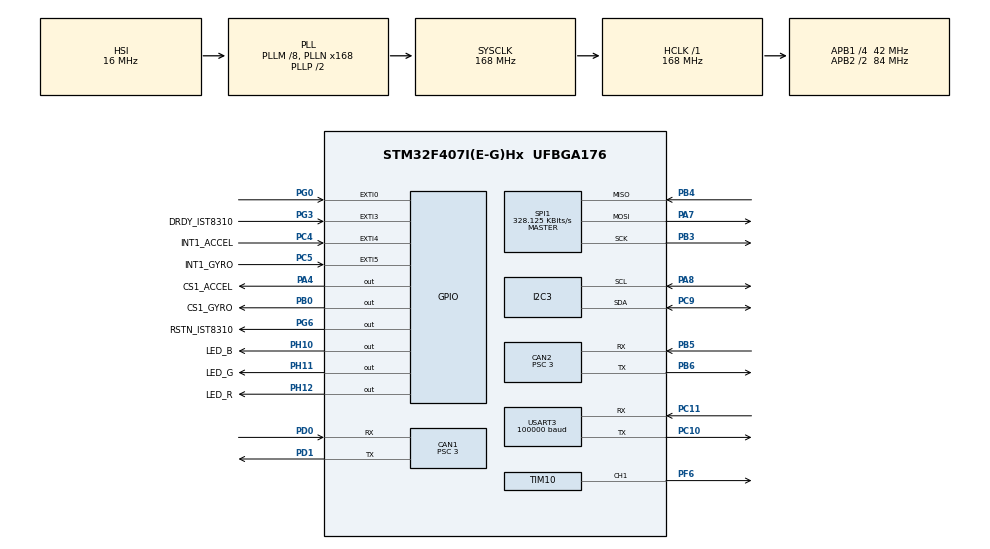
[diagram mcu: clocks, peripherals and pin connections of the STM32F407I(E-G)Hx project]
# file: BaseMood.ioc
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CAN1.BS1=CAN_BS1_11TQ
CAN1.BS2=CAN_BS2_2TQ
CAN1.CalculateBaudRate=1000000
CAN1.CalculateTimeBit=1000
CAN1.CalculateTimeQuantum=71.42857142857143
CAN1.Prescaler=3
CAN2.BS1=CAN_BS1_11TQ
CAN2.BS2=CAN_BS2_2TQ
CAN2.CalculateBaudRate=1000000
CAN2.CalculateTimeBit=1000
CAN2.CalculateTimeQuantum=71.42857142857143
CAN2.Prescaler=3
Dma.Request0=SPI1_RX
Dma.Request1=SPI1_TX
Dma.Request2=USART3_RX
Dma.SPI1_RX.0.Direction=DMA_PERIPH_TO_MEMORY
Dma.SPI1_RX.0.FIFOMode=DMA_FIFOMODE_DISABLE
Dma.SPI1_RX.0.Instance=DMA2_Stream2
Dma.SPI1_RX.0.MemDataAlignment=DMA_MDATAALIGN_BYTE
Dma.SPI1_RX.0.MemInc=DMA_MINC_ENABLE
Dma.SPI1_RX.0.Mode=DMA_NORMAL
Dma.SPI1_RX.0.PeriphDataAlignment=DMA_PDATAALIGN_BYTE
Dma.SPI1_RX.0.PeriphInc=DMA_PINC_DISABLE
Dma.SPI1_RX.0.Priority=DMA_PRIORITY_VERY_HIGH
Dma.SPI1_TX.1.Direction=DMA_MEMORY_TO_PERIPH
Dma.SPI1_TX.1.FIFOMode=DMA_FIFOMODE_DISABLE
Dma.SPI1_TX.1.Instance=DMA2_Stream3
Dma.SPI1_TX.1.MemDataAlignment=DMA_MDATAALIGN_BYTE
Dma.SPI1_TX.1.MemInc=DMA_MINC_ENABLE
Dma.SPI1_TX.1.Mode=DMA_NORMAL
Dma.SPI1_TX.1.PeriphDataAlignment=DMA_PDATAALIGN_BYTE
Dma.SPI1_TX.1.PeriphInc=DMA_PINC_DISABLE
Dma.SPI1_TX.1.Priority=DMA_PRIORITY_HIGH
Dma.USART3_RX.2.Direction=DMA_PERIPH_TO_MEMORY
Dma.USART3_RX.2.FIFOMode=DMA_FIFOMODE_DISABLE
Dma.USART3_RX.2.Instance=DMA1_Stream1
Dma.USART3_RX.2.MemDataAlignment=DMA_MDATAALIGN_BYTE
Dma.USART3_RX.2.MemInc=DMA_MINC_ENABLE
Dma.USART3_RX.2.Mode=DMA_CIRCULAR
Dma.USART3_RX.2.PeriphDataAlignment=DMA_PDATAALIGN_BYTE
Dma.USART3_RX.2.PeriphInc=DMA_PINC_DISABLE
Dma.USART3_RX.2.Priority=DMA_PRIORITY_MEDIUM
FREERTOS.INCLUDE_pcTaskGetTaskName=1
FREERTOS.INCLUDE_uxTaskGetStackHighWaterMark2=1
FREERTOS.INCLUDE_vTaskCleanUpResources=1
FREERTOS.INCLUDE_xEventGroupSetBitFromISR=1
FREERTOS.INCLUDE_xSemaphoreGetMutexHolder=1
FREERTOS.INCLUDE_xTaskAbortDelay=1
FREERTOS.INCLUDE_xTaskGetHandle=1
FREERTOS.Queues01=Queue_DJI_MD,5,uint16_t,0,Static,myQueue01testBuffer,myQueue01testControlBlock;g_CAN2_Queue,16,uint16_t,0,Static,g_CAN2_QueueBuffer,g_CAN2_QueueControlBlock
FREERTOS.Tasks01=defaultTask,24,128,StartDefaultTask,Default,NULL,Dynamic,NULL,NULL;RealTime_TASK,24,128,StartRealTime_TASK,As weak,NULL,Static,RealTime_TASKBuffer,RealTime_TASKControlBlock;DJI_RecieveData,24,128,Start_DJI_RecieveData,As weak,NULL,Static,DJI_RecieveDataBuffer,DJI_RecieveDataControlBlock;imuTask,49,1024,INS_task,Default,NULL,Dynamic,NULL,NULL;buzr,24,128,buzzer_effects_task,Default,NULL,Dynamic,NULL,NULL;DualBoard,49,256,Dual_Board_Transmit_Task,As weak,NULL,Static,Dual_Board_TranBuffer,Dual_Board_TranControlBlock;HEROChassis,47,128,HEROChassisTask,As weak,NULL,Static,HERO_DriveSysteBuffer,HERO_DriveSysteControlBlock;HEROGimbal,47,128,HEROGimbalTask,As weak,NULL,Static,HEROGimbalBuffer,HEROGimbalControlBlock;HEROShooting,47,128,HEROShootingTask,As weak,NULL,Static,HEROShootingBuffer,HEROShootingControlBlock;HEROSystem,47,128,HEROSystemTask,As weak,NULL,Static,HEROSystemBuffer,HEROSystemControlBlock;HERODial,47,128,HERODialTask,As weak,NULL,Static,HERODialBuffer,HERODialControlBlock
I2C3.I2C_Mode=I2C_Fast
Mcu.Family=STM32F4
Mcu.Name=STM32F407I(E-G)Hx
Mcu.Package=UFBGA176
NVIC.CAN1_RX0_IRQn=true\:6\:0\:true\:false\:true\:true\:true\:true\:true
NVIC.CAN1_RX1_IRQn=true\:6\:0\:true\:false\:true\:true\:true\:true\:true
NVIC.CAN2_RX0_IRQn=true\:6\:0\:true\:false\:true\:true\:true\:true\:true
NVIC.CAN2_RX1_IRQn=true\:6\:0\:true\:false\:true\:true\:true\:true\:true
NVIC.DMA1_Stream1_IRQn=true\:15\:0\:true\:false\:true\:true\:false\:true\:true
NVIC.DMA2_Stream2_IRQn=true\:5\:0\:true\:false\:false\:false\:false\:true\:true
NVIC.DMA2_Stream3_IRQn=true\:5\:0\:false\:false\:false\:true\:false\:true\:true
NVIC.EXTI0_IRQn=true\:5\:0\:false\:false\:true\:true\:true\:true\:true
NVIC.EXTI3_IRQn=true\:5\:0\:false\:false\:true\:true\:true\:true\:true
NVIC.EXTI4_IRQn=true\:5\:0\:false\:false\:true\:true\:true\:true\:true
NVIC.EXTI9_5_IRQn=true\:5\:0\:false\:false\:true\:true\:true\:true\:true
NVIC.PriorityGroup=NVIC_PRIORITYGROUP_4
NVIC.TIM2_IRQn=true\:15\:0\:false\:false\:true\:false\:true\:true\:true
NVIC.TimeBase=TIM2_IRQn
NVIC.TimeBaseIP=TIM2
NVIC.USART3_IRQn=true\:15\:0\:true\:false\:true\:true\:true\:true\:true
PA13.Mode=Serial_Wire
PA13.Signal=SYS_JTMS-SWDIO
PA14.Mode=Serial_Wire
PA14.Signal=SYS_JTCK-SWCLK
PA4.GPIO_Label=CS1_ACCEL
PA4.GPIO_PuPd=GPIO_PULLUP
PA4.GPIO_Speed=GPIO_SPEED_FREQ_HIGH
PA4.PinState=GPIO_PIN_SET
PA4.Signal=GPIO_Output
PA7.Mode=Full_Duplex_Master
PA7.Signal=SPI1_MOSI
PA8.GPIO_Pu=GPIO_PULLUP
PA8.Mode=I2C
PA8.Signal=I2C3_SCL
PB0.GPIO_Label=CS1_GYRO
PB0.GPIO_PuPd=GPIO_PULLUP
PB0.GPIO_Speed=GPIO_SPEED_FREQ_HIGH
PB0.PinState=GPIO_PIN_SET
PB0.Signal=GPIO_Output
PB3.Mode=Full_Duplex_Master
PB3.Signal=SPI1_SCK
PB4.Mode=Full_Duplex_Master
PB4.Signal=SPI1_MISO
PB5.Mode=CAN_Activate
PB5.Signal=CAN2_RX
PB6.Mode=CAN_Activate
PB6.Signal=CAN2_TX
PC10.Mode=Asynchronous
PC10.Signal=USART3_TX
PC11.Mode=Asynchronous
PC11.Signal=USART3_RX
PC4.GPIO_Label=INT1_ACCEL
PC4.GPIO_ModeDefaultEXTI=GPIO_MODE_IT_FALLING
PC4.GPIO_PuPd=GPIO_PULLUP
PC4.Signal=GPXTI4
PC5.GPIO_Label=INT1_GYRO
PC5.GPIO_ModeDefaultEXTI=GPIO_MODE_IT_FALLING
PC5.GPIO_PuPd=GPIO_PULLUP
PC5.Signal=GPXTI5
PC9.GPIO_Pu=GPIO_PULLUP
PC9.Mode=I2C
PC9.Signal=I2C3_SDA
PD0.Mode=CAN_Activate
PD0.Signal=CAN1_RX
PD1.Mode=CAN_Activate
PD1.Signal=CAN1_TX
PF6.Signal=S_TIM10_CH1
PG0.GPIO_ModeDefaultEXTI=GPIO_MODE_IT_FALLING
PG0.GPIO_PuPd=GPIO_PULLUP
PG0.Signal=GPXTI0
PG3.GPIO_Label=DRDY_IST8310
PG3.GPIO_PuPd=GPIO_PULLUP
PG3.Signal=GPXTI3
PG6.GPIO_Label=RSTN_IST8310
PG6.GPIO_PuPd=GPIO_PULLUP
PG6.GPIO_Speed=GPIO_SPEED_FREQ_MEDIUM
PG6.PinState=GPIO_PIN_SET
PG6.Signal=GPIO_Output
PH10.GPIO_Label=LED_B
PH10.GPIO_PuPd=GPIO_PULLUP
PH10.Signal=GPIO_Output
PH11.GPIO_Label=LED_G
PH11.Signal=GPIO_Output
PH12.GPIO_Label=LED_R
PH12.Signal=GPIO_Output
ProjectManager.HeapSize=0x200
ProjectManager.StackSize=0x400
ProjectManager.TargetToolchain=MDK-ARM V5.32
RCC.48MHZClocksFreq_Value=84000000
RCC.AHBFreq_Value=168000000
RCC.APB1CLKDivider=RCC_HCLK_DIV4
RCC.APB1Freq_Value=42000000
RCC.APB1TimFreq_Value=84000000
RCC.APB2CLKDivider=RCC_HCLK_DIV2
RCC.APB2Freq_Value=84000000
RCC.APB2TimFreq_Value=168000000
RCC.CortexFreq_Value=168000000
RCC.HCLKFreq_Value=168000000
RCC.HSE_VALUE=25000000
RCC.HSI_VALUE=16000000
RCC.LSE_VALUE=32768
RCC.PLLM=8
RCC.PLLN=168
RCC.SYSCLKFreq_VALUE=168000000
RCC.SYSCLKSource=RCC_SYSCLKSOURCE_PLLCLK
RCC.VCOOutputFreq_Value=336000000
SH.S_TIM10_CH1.0=TIM10_CH1,PWM Generation1 CH1
SPI1.BaudRatePrescaler=SPI_BAUDRATEPRESCALER_256
SPI1.CLKPhase=SPI_PHASE_2EDGE
SPI1.CLKPolarity=SPI_POLARITY_HIGH
SPI1.CalculateBaudRate=328.125 KBits/s
SPI1.Direction=SPI_DIRECTION_2LINES
SPI1.Mode=SPI_MODE_MASTER
SPI1.VirtualType=VM_MASTER
TIM10.Channel=TIM_CHANNEL_1
TIM10.Period=4999
USART3.BaudRate=100000
USART3.Parity=PARITY_EVEN
USART3.StopBits=STOPBITS_2
USART3.VirtualMode=VM_ASYNC
USART3.WordLength=WORDLENGTH_9B
VP_FREERTOS_VS_CMSIS_V2.Mode=CMSIS_V2
VP_SYS_VS_tim2.Mode=TIM2
VP_TIM10_VS_ClockSourceINT.Mode=Enable_Timer
board=custom

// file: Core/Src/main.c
/* USER CODE BEGIN Header */
/**
  ******************************************************************************
  * @file           : main.c
  * @brief          : Main program body
  ******************************************************************************
  * @attention
  *
  * Copyright (c) 2026 STMicroelectronics.
  * All rights reserved.
  *
  * This software is licensed under terms that can be found in the LICENSE file
  * in the root directory of this software component.
  * If no LICENSE file comes with this software, it is provided AS-IS.
  *
  ******************************************************************************
  */
/* USER CODE END Header */
#include "main.h"
#include "cmsis_os.h"
#include "can.h"
#include "dma.h"
#include "i2c.h"
#include "spi.h"
#include "tim.h"
#include "usart.h"
#include "gpio.h"

/* USER CODE BEGIN Includes */
#include "bsp_delay.h"
#include "MY_Time.h"
#include "UAP_Init.h"
#include "UAP_FreeRTOS.h"

//#include "CAN_PART.h"
//#include "DJI_Motor.h"

/* USER CODE END Includes */

void SystemClock_Config(void);
void MX_FREERTOS_Init(void);

int main(void)
{

  /* MCU Configuration--------------------------------------------------------*/

  /* Reset of all peripherals, Initializes the Flash interface and the Systick. */
  HAL_Init();

  /* Configure the system clock */
  SystemClock_Config();

  /* Initialize all configured peripherals */
  MX_GPIO_Init();
  MX_DMA_Init();
  MX_CAN1_Init();
  MX_CAN2_Init();
  MX_SPI1_Init();
  MX_I2C3_Init();
  MX_TIM10_Init();
  MX_USART3_UART_Init();
  /* USER CODE BEGIN 2 */
	delay_init();
	UAP_Init();

  /* USER CODE END 2 */

  /* Init scheduler */
  osKernelInitialize();

  /* Call init function for freertos objects (in cmsis_os2.c) */
  MX_FREERTOS_Init();

  /* Start scheduler */
  osKernelStart();

  /* We should never get here as control is now taken by the scheduler */

  /* Infinite loop */
  while (1)
  {

  }
}

void SystemClock_Config(void)
{
  RCC_OscInitTypeDef RCC_OscInitStruct = {0};
  RCC_ClkInitTypeDef RCC_ClkInitStruct = {0};

  /** Configure the main internal regulator output voltage
  */
  __HAL_RCC_PWR_CLK_ENABLE();
  __HAL_PWR_VOLTAGESCALING_CONFIG(PWR_REGULATOR_VOLTAGE_SCALE1);

  /** Initializes the RCC Oscillators according to the specified parameters
  * in the RCC_OscInitTypeDef structure.
  */
  RCC_OscInitStruct.OscillatorType = RCC_OSCILLATORTYPE_HSI;
  RCC_OscInitStruct.HSIState = RCC_HSI_ON;
  RCC_OscInitStruct.HSICalibrationValue = RCC_HSICALIBRATION_DEFAULT;
  RCC_OscInitStruct.PLL.PLLState = RCC_PLL_ON;
  RCC_OscInitStruct.PLL.PLLSource = RCC_PLLSOURCE_HSI;
  RCC_OscInitStruct.PLL.PLLM = 8;
  RCC_OscInitStruct.PLL.PLLN = 168;
  RCC_OscInitStruct.PLL.PLLP = RCC_PLLP_DIV2;
  RCC_OscInitStruct.PLL.PLLQ = 4;
  if (HAL_RCC_OscConfig(&RCC_OscInitStruct) != HAL_OK)
  {
    Error_Handler();
  }

  /** Initializes the CPU, AHB and APB buses clocks
  */
  RCC_ClkInitStruct.ClockType = RCC_CLOCKTYPE_HCLK|RCC_CLOCKTYPE_SYSCLK
                              |RCC_CLOCKTYPE_PCLK1|RCC_CLOCKTYPE_PCLK2;
  RCC_ClkInitStruct.SYSCLKSource = RCC_SYSCLKSOURCE_PLLCLK;
  RCC_ClkInitStruct.AHBCLKDivider = RCC_SYSCLK_DIV1;
  RCC_ClkInitStruct.APB1CLKDivider = RCC_HCLK_DIV4;
  RCC_ClkInitStruct.APB2CLKDivider = RCC_HCLK_DIV2;

  if (HAL_RCC_ClockConfig(&RCC_ClkInitStruct, FLASH_LATENCY_5) != HAL_OK)
  {
    Error_Handler();
  }
}

void HAL_TIM_PeriodElapsedCallback(TIM_HandleTypeDef *htim)
{
  if (htim->Instance == TIM2)
  {
    HAL_IncTick();
  }
}

void Error_Handler(void)
{
  __disable_irq();
  while (1)
  {
  }
}

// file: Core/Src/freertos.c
/* USER CODE BEGIN Header */
/**
  ******************************************************************************
  * File Name          : freertos.c
  * Description        : Code for freertos applications
  ******************************************************************************
  * @attention
  *
  * Copyright (c) 2026 STMicroelectronics.
  * All rights reserved.
  *
  * This software is licensed under terms that can be found in the LICENSE file
  * in the root directory of this software component.
  * If no LICENSE file comes with this software, it is provided AS-IS.
  *
  ******************************************************************************
  */
/* USER CODE END Header */

#include "FreeRTOS.h"
#include "task.h"
#include "main.h"
#include "cmsis_os.h"

/* USER CODE BEGIN Includes */
#include "INS_task.h"
#include "MY_LED.h"
#include "DJI_Motor_CAN.h"
#include "sound_effects_task.h"
#include "Dual_board_Transmit.h"
#include "HERO_DriveSystem.h"

#include "User_CanCallBack.h"

/* USER CODE END Includes */

typedef StaticTask_t osStaticThreadDef_t;
typedef StaticQueue_t osStaticMessageQDef_t;

/* Definitions for defaultTask */
osThreadId_t defaultTaskHandle;
const osThreadAttr_t defaultTask_attributes = {
  .name = "defaultTask",
  .stack_size = 128 * 4,
  .priority = (osPriority_t) osPriorityNormal,
};
/* Definitions for RealTime_TASK */
osThreadId_t RealTime_TASKHandle;
uint32_t RealTime_TASKBuffer[ 128 ];
osStaticThreadDef_t RealTime_TASKControlBlock;
const osThreadAttr_t RealTime_TASK_attributes = {
  .name = "RealTime_TASK",
  .cb_mem = &RealTime_TASKControlBlock,
  .cb_size = sizeof(RealTime_TASKControlBlock),
  .stack_mem = &RealTime_TASKBuffer[0],
  .stack_size = sizeof(RealTime_TASKBuffer),
  .priority = (osPriority_t) osPriorityNormal,
};
/* Definitions for DJI_RecieveData */
osThreadId_t DJI_RecieveDataHandle;
uint32_t DJI_RecieveDataBuffer[ 128 ];
osStaticThreadDef_t DJI_RecieveDataControlBlock;
const osThreadAttr_t DJI_RecieveData_attributes = {
  .name = "DJI_RecieveData",
  .cb_mem = &DJI_RecieveDataControlBlock,
  .cb_size = sizeof(DJI_RecieveDataControlBlock),
  .stack_mem = &DJI_RecieveDataBuffer[0],
  .stack_size = sizeof(DJI_RecieveDataBuffer),
  .priority = (osPriority_t) osPriorityNormal,
};
/* Definitions for imuTask */
osThreadId_t imuTaskHandle;
const osThreadAttr_t imuTask_attributes = {
  .name = "imuTask",
  .stack_size = 1024 * 4,
  .priority = (osPriority_t) osPriorityRealtime1,
};
/* Definitions for buzr */
osThreadId_t buzrHandle;
const osThreadAttr_t buzr_attributes = {
  .name = "buzr",
  .stack_size = 128 * 4,
  .priority = (osPriority_t) osPriorityNormal,
};
/* Definitions for DualBoard */
osThreadId_t DualBoardHandle;
uint32_t Dual_Board_TranBuffer[ 256 ];
osStaticThreadDef_t Dual_Board_TranControlBlock;
const osThreadAttr_t DualBoard_attributes = {
  .name = "DualBoard",
  .cb_mem = &Dual_Board_TranControlBlock,
  .cb_size = sizeof(Dual_Board_TranControlBlock),
  .stack_mem = &Dual_Board_TranBuffer[0],
  .stack_size = sizeof(Dual_Board_TranBuffer),
  .priority = (osPriority_t) osPriorityRealtime1,
};
/* Definitions for HEROChassis */
osThreadId_t HEROChassisHandle;
uint32_t HERO_DriveSysteBuffer[ 128 ];
osStaticThreadDef_t HERO_DriveSysteControlBlock;
const osThreadAttr_t HEROChassis_attributes = {
  .name = "HEROChassis",
  .cb_mem = &HERO_DriveSysteControlBlock,
  .cb_size = sizeof(HERO_DriveSysteControlBlock),
  .stack_mem = &HERO_DriveSysteBuffer[0],
  .stack_size = sizeof(HERO_DriveSysteBuffer),
  .priority = (osPriority_t) osPriorityHigh7,
};
/* Definitions for HEROGimbal */
osThreadId_t HEROGimbalHandle;
uint32_t HEROGimbalBuffer[ 128 ];
osStaticThreadDef_t HEROGimbalControlBlock;
const osThreadAttr_t HEROGimbal_attributes = {
  .name = "HEROGimbal",
  .cb_mem = &HEROGimbalControlBlock,
  .cb_size = sizeof(HEROGimbalControlBlock),
  .stack_mem = &HEROGimbalBuffer[0],
  .stack_size = sizeof(HEROGimbalBuffer),
  .priority = (osPriority_t) osPriorityHigh7,
};
/* Definitions for HEROShooting */
osThreadId_t HEROShootingHandle;
uint32_t HEROShootingBuffer[ 128 ];
osStaticThreadDef_t HEROShootingControlBlock;
const osThreadAttr_t HEROShooting_attributes = {
  .name = "HEROShooting",
  .cb_mem = &HEROShootingControlBlock,
  .cb_size = sizeof(HEROShootingControlBlock),
  .stack_mem = &HEROShootingBuffer[0],
  .stack_size = sizeof(HEROShootingBuffer),
  .priority = (osPriority_t) osPriorityHigh7,
};
/* Definitions for HEROSystem */
osThreadId_t HEROSystemHandle;
uint32_t HEROSystemBuffer[ 128 ];
osStaticThreadDef_t HEROSystemControlBlock;
const osThreadAttr_t HEROSystem_attributes = {
  .name = "HEROSystem",
  .cb_mem = &HEROSystemControlBlock,
  .cb_size = sizeof(HEROSystemControlBlock),
  .stack_mem = &HEROSystemBuffer[0],
  .stack_size = sizeof(HEROSystemBuffer),
  .priority = (osPriority_t) osPriorityHigh7,
};
/* Definitions for HERODial */
osThreadId_t HERODialHandle;
uint32_t HERODialBuffer[ 128 ];
osStaticThreadDef_t HERODialControlBlock;
const osThreadAttr_t HERODial_attributes = {
  .name = "HERODial",
  .cb_mem = &HERODialControlBlock,
  .cb_size = sizeof(HERODialControlBlock),
  .stack_mem = &HERODialBuffer[0],
  .stack_size = sizeof(HERODialBuffer),
  .priority = (osPriority_t) osPriorityHigh7,
};
/* Definitions for Queue_DJI_MD */
osMessageQueueId_t Queue_DJI_MDHandle;
uint8_t myQueue01testBuffer[ 5 * sizeof( uint16_t ) ];
osStaticMessageQDef_t myQueue01testControlBlock;
const osMessageQueueAttr_t Queue_DJI_MD_attributes = {
  .name = "Queue_DJI_MD",
  .cb_mem = &myQueue01testControlBlock,
  .cb_size = sizeof(myQueue01testControlBlock),
  .mq_mem = &myQueue01testBuffer,
  .mq_size = sizeof(myQueue01testBuffer)
};
/* Definitions for g_CAN2_Queue */
osMessageQueueId_t g_CAN2_QueueHandle;
uint8_t g_CAN2_QueueBuffer[ 16 * sizeof( uint16_t ) ];
osStaticMessageQDef_t g_CAN2_QueueControlBlock;
const osMessageQueueAttr_t g_CAN2_Queue_attributes = {
  .name = "g_CAN2_Queue",
  .cb_mem = &g_CAN2_QueueControlBlock,
  .cb_size = sizeof(g_CAN2_QueueControlBlock),
  .mq_mem = &g_CAN2_QueueBuffer,
  .mq_size = sizeof(g_CAN2_QueueBuffer)
};

void StartDefaultTask(void *argument);
void StartRealTime_TASK(void *argument);
void Start_DJI_RecieveData(void *argument);
void Dual_Board_Transmit_Task(void *argument);
void HEROChassisTask(void *argument);
void HEROGimbalTask(void *argument);
void HEROShootingTask(void *argument);
void HEROSystemTask(void *argument);
void HERODialTask(void *argument);

void MX_FREERTOS_Init(void); /* (MISRA C 2004 rule 8.1) */

void MX_FREERTOS_Init(void) {

  /* Create the queue(s) */
  /* creation of Queue_DJI_MD */
  Queue_DJI_MDHandle = osMessageQueueNew (5, sizeof(uint16_t), &Queue_DJI_MD_attributes);

  /* creation of g_CAN2_Queue */
  g_CAN2_QueueHandle = osMessageQueueNew (16, sizeof(uint16_t), &g_CAN2_Queue_attributes);

  /* Create the thread(s) */
  /* creation of defaultTask */
  defaultTaskHandle = osThreadNew(StartDefaultTask, NULL, &defaultTask_attributes);

  /* creation of RealTime_TASK */
  RealTime_TASKHandle = osThreadNew(StartRealTime_TASK, NULL, &RealTime_TASK_attributes);

  /* creation of DJI_RecieveData */
  DJI_RecieveDataHandle = osThreadNew(Start_DJI_RecieveData, NULL, &DJI_RecieveData_attributes);

  /* creation of imuTask */
  imuTaskHandle = osThreadNew(INS_task, NULL, &imuTask_attributes);

  /* creation of buzr */
  buzrHandle = osThreadNew(buzzer_effects_task, NULL, &buzr_attributes);

  /* creation of DualBoard */
  DualBoardHandle = osThreadNew(Dual_Board_Transmit_Task, NULL, &DualBoard_attributes);

  /* creation of HEROChassis */
  HEROChassisHandle = osThreadNew(HEROChassisTask, NULL, &HEROChassis_attributes);

  /* creation of HEROGimbal */
  HEROGimbalHandle = osThreadNew(HEROGimbalTask, NULL, &HEROGimbal_attributes);

  /* creation of HEROShooting */
  HEROShootingHandle = osThreadNew(HEROShootingTask, NULL, &HEROShooting_attributes);

  /* creation of HEROSystem */
  HEROSystemHandle = osThreadNew(HEROSystemTask, NULL, &HEROSystem_attributes);

  /* creation of HERODial */
  HERODialHandle = osThreadNew(HERODialTask, NULL, &HERODial_attributes);

}

void StartDefaultTask(void *argument)
{
  /* USER CODE BEGIN StartDefaultTask */
  /* Infinite loop */

//	static uint16_t timecounttest = 0;
//	buzzer_t *buzzer = get_buzzer_effect_point();
//	buzzer->work = FALSE;
//	buzzer->work = TRUE;

  for(;;)
  {
    osDelay(10);
  }
  /* USER CODE END StartDefaultTask */
}

__weak void StartRealTime_TASK(void *argument)
{
  for(;;)
  {
    osDelay(1);
  }
}

__weak void Start_DJI_RecieveData(void *argument)
{
  for(;;)
  {
    osDelay(1);
  }
}

__weak void Dual_Board_Transmit_Task(void *argument)
{
  for(;;)
  {
    osDelay(1);
  }
}

__weak void HEROChassisTask(void *argument)
{
  for(;;)
  {
    osDelay(1);
  }
}

__weak void HEROGimbalTask(void *argument)
{
  for(;;)
  {
    osDelay(1);
  }
}

__weak void HEROShootingTask(void *argument)
{
  for(;;)
  {
    osDelay(1);
  }
}

__weak void HEROSystemTask(void *argument)
{
  for(;;)
  {
    osDelay(1);
  }
}

__weak void HERODialTask(void *argument)
{
  for(;;)
  {
    osDelay(1);
  }
}
